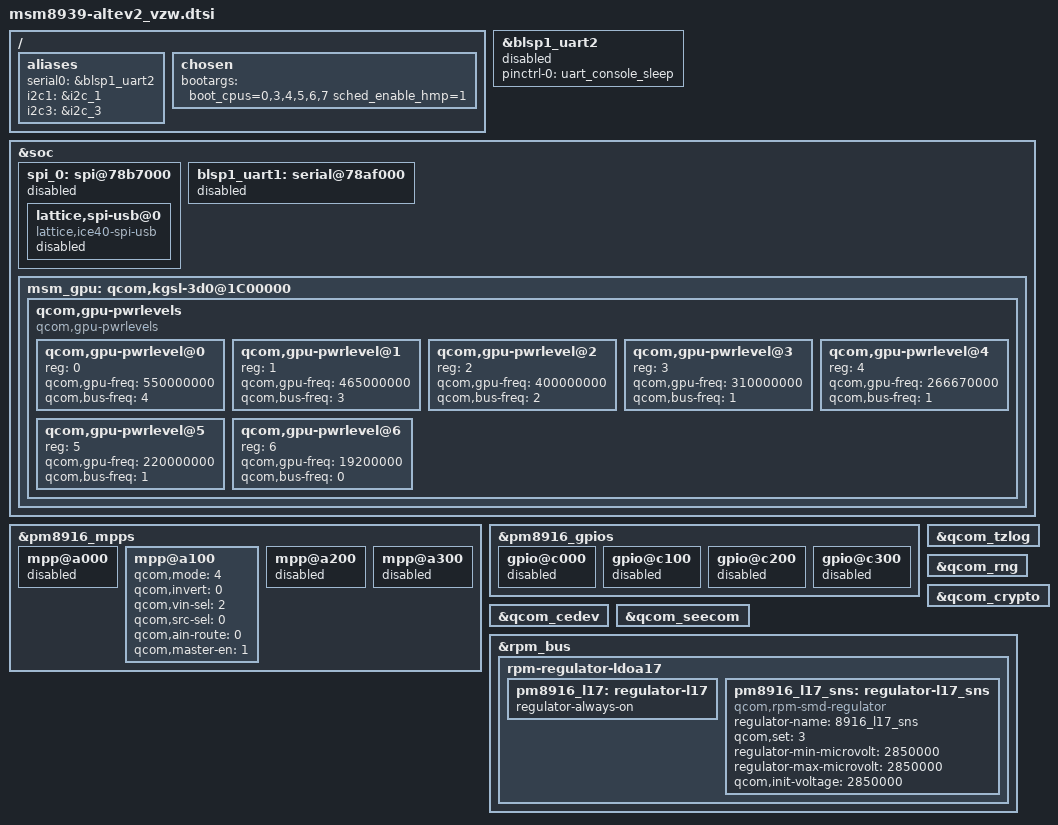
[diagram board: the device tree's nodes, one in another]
/* Copyright (c) 2014, The Linux Foundation. All rights reserved.
 *
 * This program is free software; you can redistribute it and/or modify
 * it under the terms of the GNU General Public License version 2 and
 * only version 2 as published by the Free Software Foundation.
 *
 * This program is distributed in the hope that it will be useful,
 * but WITHOUT ANY WARRANTY; without even the implied warranty of
 * MERCHANTABILITY or FITNESS FOR A PARTICULAR PURPOSE.  See the
 * GNU General Public License for more details.
 */


#include "msm8939-altev2_vzw-pinctrl.dtsi"

/ {
	aliases {
		serial0 = &blsp1_uart2;
		i2c1 = &i2c_1; /* i2c_1 BLSP1 QUP1 */
		i2c3 = &i2c_3; /* i2c_3 BLSP1 QUP3 */
	};
    chosen {
             bootargs = "boot_cpus=0,3,4,5,6,7 sched_enable_hmp=1";
    };

};

&blsp1_uart2 {
	status = "disabled";
	pinctrl-names = "default";
	pinctrl-0 = <&uart_console_sleep>;
};

&soc {
	spi_0: spi@78b7000 { /* BLSP1 QUP3 */
		status = "disabled";
		lattice,spi-usb@0 {
			compatible = "lattice,ice40-spi-usb";
			status = "disabled";
		};
	};
	blsp1_uart1: serial@78af000 {
		status = "disabled";
	};
	msm_gpu: qcom,kgsl-3d0@1C00000 {
		/* Power levels */
		qcom,gpu-pwrlevels {
			#address-cells = <1>;
			#size-cells = <0>;

			compatible = "qcom,gpu-pwrlevels";

			qcom,gpu-pwrlevel@0 {
				reg = <0>;
				qcom,gpu-freq = <550000000>;
				qcom,bus-freq = <4>;
			};

			qcom,gpu-pwrlevel@1 {
				reg = <1>;
				qcom,gpu-freq = <465000000>;
				qcom,bus-freq = <3>;
			};

			qcom,gpu-pwrlevel@2 {
				reg = <2>;
				qcom,gpu-freq = <400000000>;
				qcom,bus-freq = <2>;
			};

			qcom,gpu-pwrlevel@3 {
				reg = <3>;
				qcom,gpu-freq = <310000000>;
				qcom,bus-freq = <1>;
			};

			qcom,gpu-pwrlevel@4 {
				reg = <4>;
				qcom,gpu-freq = <266670000>;
				qcom,bus-freq = <1>;
			};

			qcom,gpu-pwrlevel@5 {
				reg = <5>;
				qcom,gpu-freq = <220000000>;
				qcom,bus-freq = <1>;
			};

			qcom,gpu-pwrlevel@6 {
				reg = <6>;
				qcom,gpu-freq = <19200000>;
				qcom,bus-freq = <0>;
			};
		};
	};
};

&pm8916_mpps {
	mpp@a000 { /* MPP 1 */
		/* VDD_PX */
		status = "disabled";
	};

	mpp@a100 { /* MPP 2 */
		/* USB ID */
                status = "ok";
                qcom,mode = <4>;
                qcom,invert = <0>;
                qcom,vin-sel = <2>;
                qcom,src-sel = <0>;
                qcom,ain-route = <0>;
                qcom,master-en = <1>;
	};

	mpp@a200 { /* MPP 3 */
		/* VREF DAC */
		status = "disabled";
	};

	mpp@a300 { /* MPP 4 */
		/* HW Revision */
		status = "disabled";
	};
};

&pm8916_gpios {
	gpio@c000 { /* GPIO 1 */
		/* Battery UICC Alarm */
		status = "disabled";
	};

	gpio@c100 { /* GPIO 2 */
		status = "disabled";
	};

	gpio@c200 { /* GPIO 3 */
		/* External regulator control for WTR */
		status = "disabled";
	};

	gpio@c300 { /* GPIO 4 */
		/* External regulator control for APC */
		status = "disabled";
	};
};

&qcom_tzlog {
	status = "okay";
};

&qcom_rng {
	status = "okay";
};

&qcom_crypto {
	status = "okay";
};

&qcom_cedev {
	status = "okay";
};

&qcom_seecom {
	status = "okay";
};

&rpm_bus {
	rpm-regulator-ldoa17 {
		status = "ok";
		pm8916_l17: regulator-l17 {
			status = "ok";
			regulator-always-on;
		};

		pm8916_l17_sns: regulator-l17_sns {
			status = "ok";
			compatible = "qcom,rpm-smd-regulator";
			regulator-name = "8916_l17_sns";
			qcom,set = <3>;
			regulator-min-microvolt = <2850000>;
			regulator-max-microvolt = <2850000>;
			qcom,init-voltage = <2850000>;
		};
	};
};
#include "../msm8939-common.dtsi"
#include "msm8939-altev2_vzw-panel.dtsi"
#include "msm8939-altev2_vzw-sensor.dtsi"
#include "msm8939-altev2_vzw-usb.dtsi"
#include "msm8939-altev2_vzw-input.dtsi"
#include "msm8939-altev2_vzw-misc.dtsi"
#include "msm8939-altev2_vzw-pm.dtsi"
#include "msm8939-altev2_vzw-camera.dtsi"
#include "msm8939-altev2_vzw-connectivity.dtsi"
#include "msm8939-altev2_vzw-sound.dtsi"
#include "msm8939-altev2_vzw-nfc.dtsi"
